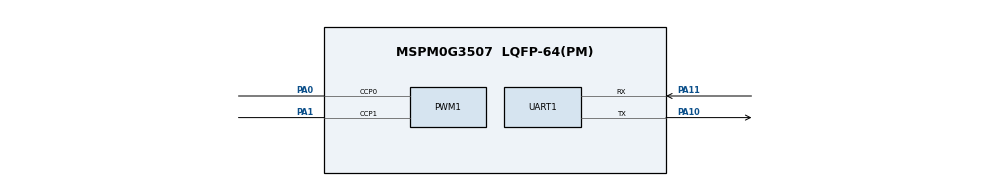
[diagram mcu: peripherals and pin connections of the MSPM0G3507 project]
/**
 * These arguments were used when this file was generated. They will be automatically applied on subsequent loads
 * via the GUI or CLI. Run CLI with '--help' for additional information on how to override these arguments.
 * @cliArgs --device "MSPM0G350X" --part "Default" --package "LQFP-64(PM)" --product "mspm0_sdk@2.10.00.04"
 * @v2CliArgs --device "MSPM0G3507" --package "LQFP-64(PM)" --product "mspm0_sdk@2.10.00.04"
 * @versions {"tool":"1.26.2+4477"}
 */

/**
 * Import the modules used in this configuration.
 */
const ADC12  = scripting.addModule("/ti/driverlib/ADC12", {}, false);
const ADC121 = ADC12.addInstance();
const GPIO   = scripting.addModule("/ti/driverlib/GPIO", {}, false);
const GPIO1  = GPIO.addInstance();
const GPIO2  = GPIO.addInstance();
const GPIO3  = GPIO.addInstance();
const GPIO4  = GPIO.addInstance();
const GPIO5  = GPIO.addInstance();
const GPIO6  = GPIO.addInstance();
const PWM    = scripting.addModule("/ti/driverlib/PWM", {}, false);
const PWM1   = PWM.addInstance();
const SYSCTL = scripting.addModule("/ti/driverlib/SYSCTL");
const UART   = scripting.addModule("/ti/driverlib/UART", {}, false);
const UART1  = UART.addInstance();

/**
 * Write custom configuration values to the imported modules.
 */
GPIO1.$name                         = "TB6612_PORTB";
GPIO1.port                          = "PORTB";
GPIO1.associatedPins.create(2);
GPIO1.associatedPins[0].$name       = "AIN2";
GPIO1.associatedPins[0].assignedPin = "20";
GPIO1.associatedPins[1].$name       = "STBY";
GPIO1.associatedPins[1].assignedPin = "26";

const Board = scripting.addModule("/ti/driverlib/Board", {}, false);

GPIO2.$name                         = "TB6612_PORTA";
GPIO2.port                          = "PORTA";
GPIO2.associatedPins.create(3);
GPIO2.associatedPins[0].$name       = "AIN1";
GPIO2.associatedPins[0].assignedPin = "15";
GPIO2.associatedPins[1].$name       = "BIN1";
GPIO2.associatedPins[1].assignedPin = "28";
GPIO2.associatedPins[2].$name       = "BIN2";
GPIO2.associatedPins[2].assignedPin = "16";

GPIO3.$name                         = "TRACKING_SEL";
GPIO3.port                          = "PORTA";
GPIO3.associatedPins.create(3);
GPIO3.associatedPins[0].$name       = "S0";
GPIO3.associatedPins[0].assignedPin = "24";
GPIO3.associatedPins[1].$name       = "S1";
GPIO3.associatedPins[1].assignedPin = "26";
GPIO3.associatedPins[2].$name       = "S2";
GPIO3.associatedPins[2].assignedPin = "27";

GPIO4.$name                              = "ENCODER_PORTB";
GPIO4.port                               = "PORTB";
GPIO4.portSegment                        = "Lower";
GPIO4.associatedPins.create(4);
GPIO4.associatedPins[0].$name            = "LEFT_A";
GPIO4.associatedPins[0].assignedPin      = "6";
GPIO4.associatedPins[0].direction        = "INPUT";
GPIO4.associatedPins[0].internalResistor = "PULL_UP";
GPIO4.associatedPins[0].interruptEn      = true;
GPIO4.associatedPins[0].polarity         = "RISE_FALL";
GPIO4.associatedPins[1].$name            = "LEFT_B";
GPIO4.associatedPins[1].assignedPin      = "7";
GPIO4.associatedPins[1].direction        = "INPUT";
GPIO4.associatedPins[1].internalResistor = "PULL_UP";
GPIO4.associatedPins[2].$name            = "RIGHT_A";
GPIO4.associatedPins[2].assignedPin      = "8";
GPIO4.associatedPins[2].direction        = "INPUT";
GPIO4.associatedPins[2].internalResistor = "PULL_UP";
GPIO4.associatedPins[2].interruptEn      = true;
GPIO4.associatedPins[2].polarity         = "RISE_FALL";
GPIO4.associatedPins[3].$name            = "RIGHT_B";
GPIO4.associatedPins[3].assignedPin      = "9";
GPIO4.associatedPins[3].direction        = "INPUT";
GPIO4.associatedPins[3].internalResistor = "PULL_UP";

GPIO5.$name                         = "OLED_I2C";
GPIO5.port                          = "PORTB";
GPIO5.portSegment                   = "Lower";
GPIO5.associatedPins.create(2);
GPIO5.associatedPins[0].$name       = "SCL";
GPIO5.associatedPins[0].assignedPin = "10";
GPIO5.associatedPins[0].initialValue = "SET";
GPIO5.associatedPins[1].$name       = "SDA";
GPIO5.associatedPins[1].assignedPin = "11";
GPIO5.associatedPins[1].initialValue = "SET";

GPIO6.$name                         = "RUN_LED";
GPIO6.port                          = "PORTB";
GPIO6.portSegment                   = "Upper";
GPIO6.associatedPins[0].$name       = "LED";
GPIO6.associatedPins[0].assignedPin = "27";
GPIO6.associatedPins[0].initialValue = "CLEARED";

PWM1.$name                      = "PWM_0";
PWM1.timerStartTimer            = true;
PWM1.clockDivider               = 8;
PWM1.timerCount                 = 1000;
PWM1.ccIndex                    = [0,1];
PWM1.peripheral.$assign         = "TIMA0";
PWM1.peripheral.ccp0Pin.$assign = "PA0";
PWM1.peripheral.ccp1Pin.$assign = "PA1";
PWM1.PWM_CHANNEL_0.$name        = "PWMA";
PWM1.PWM_CHANNEL_0.dutyCycle    = 0;
PWM1.PWM_CHANNEL_1.$name        = "PWMB";
PWM1.PWM_CHANNEL_1.dutyCycle    = 0;

ADC121.$name                      = "ADC12_0";
ADC121.sampClkSrc                 = "DL_ADC12_CLOCK_ULPCLK";
ADC121.sampClkDiv                 = "DL_ADC12_CLOCK_DIVIDE_8";
ADC121.powerDownMode              = "DL_ADC12_POWER_DOWN_MODE_MANUAL";
ADC121.sampleTime0                = "40 us";
ADC121.adcMem0chansel             = "DL_ADC12_INPUT_CHAN_2";
ADC121.peripheral.$assign         = "ADC0";
ADC121.peripheral.adcPin2.$assign = "PA25";

UART1.$name                    = "UART_0";
UART1.enabledInterrupts        = ["RX"];
UART1.targetBaudRate           = 115200;
UART1.peripheral.$assign       = "UART0";
UART1.peripheral.rxPin.$assign = "PA11";
UART1.peripheral.txPin.$assign = "PA10";

SYSCTL.forceDefaultClkConfig = true;

/**
 * Pinmux solution for unlocked pins/peripherals. This ensures that minor changes to the automatic solver in a future
 * version of the tool will not impact the pinmux you originally saw. These lines can be completely deleted in order to
 * re-solve from scratch.
 */
GPIO1.associatedPins[0].pin.$suggestSolution = "PB20";
GPIO1.associatedPins[1].pin.$suggestSolution = "PB26";
Board.peripheral.$suggestSolution            = "DEBUGSS";
Board.peripheral.swclkPin.$suggestSolution   = "PA20";
Board.peripheral.swdioPin.$suggestSolution   = "PA19";
GPIO2.associatedPins[0].pin.$suggestSolution = "PA15";
GPIO2.associatedPins[1].pin.$suggestSolution = "PA28";
GPIO2.associatedPins[2].pin.$suggestSolution = "PA16";
GPIO3.associatedPins[0].pin.$suggestSolution = "PA24";
GPIO3.associatedPins[1].pin.$suggestSolution = "PA26";
GPIO3.associatedPins[2].pin.$suggestSolution = "PA27";
GPIO4.associatedPins[0].pin.$suggestSolution = "PB6";
GPIO4.associatedPins[1].pin.$suggestSolution = "PB7";
GPIO4.associatedPins[2].pin.$suggestSolution = "PB8";
GPIO4.associatedPins[3].pin.$suggestSolution = "PB9";
GPIO5.associatedPins[0].pin.$suggestSolution = "PB10";
GPIO5.associatedPins[1].pin.$suggestSolution = "PB11";
GPIO6.associatedPins[0].pin.$suggestSolution = "PB27";
SYSCTL.peripheral.$suggestSolution           = "SYSCTL";
UART1.peripheral.$suggestSolution            = "UART0";
UART1.peripheral.rxPin.$suggestSolution      = "PA11";
UART1.peripheral.txPin.$suggestSolution      = "PA10";
